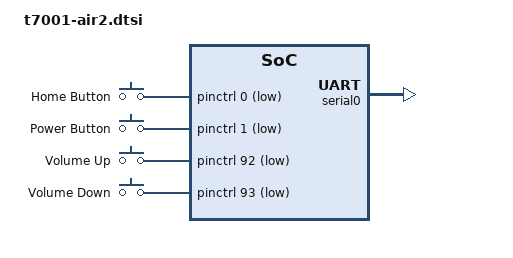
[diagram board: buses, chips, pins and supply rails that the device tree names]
// SPDX-License-Identifier: GPL-2.0+ OR MIT
/*
 * Apple iPad Air 2 common device tree
 * Copyright (c) 2022, Konrad Dybcio <konradybcio@kernel.org>
 */

#include "t7001.dtsi"
#include <dt-bindings/input/input.h>

/ {
	chassis-type = "tablet";

	gpio-keys {
		compatible = "gpio-keys";

		button-home {
			label = "Home Button";
			gpios = <&pinctrl 0 GPIO_ACTIVE_LOW>;
			linux,code = <KEY_HOMEPAGE>;
			wakeup-source;
		};

		button-power {
			label = "Power Button";
			gpios = <&pinctrl 1 GPIO_ACTIVE_LOW>;
			linux,code = <KEY_POWER>;
			wakeup-source;
		};

		button-volup {
			label = "Volume Up";
			gpios = <&pinctrl 92 GPIO_ACTIVE_LOW>;
			linux,code = <KEY_VOLUMEUP>;
		};

		button-voldown {
			label = "Volume Down";
			gpios = <&pinctrl 93 GPIO_ACTIVE_LOW>;
			linux,code = <KEY_VOLUMEDOWN>;
		};
	};
};

&serial0 {
	status = "okay";
};
